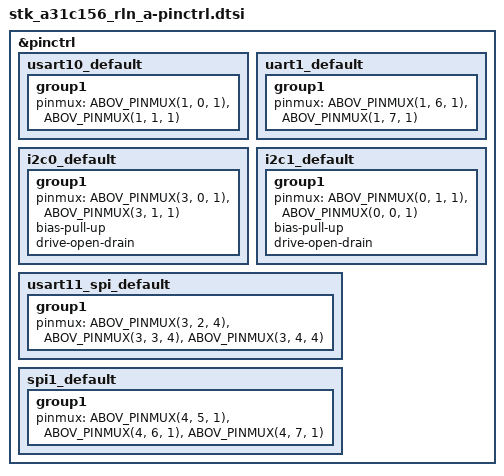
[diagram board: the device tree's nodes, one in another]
/*
 * Copyright (c) 2026 ABOV Semiconductor Co., Ltd.
 * SPDX-License-Identifier: BSD-3-Clause
 */

#include <zephyr/dt-bindings/pinctrl/abov-pinctrl.h>

&pinctrl {
	/*
	 * USART10 Pin Configuration (PB0: TX, PB1: RX, ALT1), per the default
	 * debug console pin mapping in debug_a31c15x.h (DEBUG_UART_ID=0,
	 * DEBUG_PORT_ID=1/PORT B, TX pin 0, RX pin 1, ALT 1).
	 */
	usart10_default: usart10_default {
		group1 {
			pinmux = <ABOV_PINMUX(1, 0, 1)>, /* PB0 - USART10_TX (ALT1) */
				 <ABOV_PINMUX(1, 1, 1)>; /* PB1 - USART10_RX (ALT1) */
		};
	};

	/*
	 * UART0's TX/RX pins (PF0/PF1, ALT4 -- see Board/stk_a31c156_rln_a.h)
	 * are shared with the on-board SWD debug port on this STK, so UART0
	 * is not usable here. UART1 Pin Configuration (PB6: TX, PB7: RX,
	 * ALT1) instead, per startup_a31c15x.h's P6/P7 mux comments
	 * ("0:PB6 1:TXD1" / "0:PB7 1:RXD1") and Board/bare.h's
	 * UART1_TX_PORT/UART1_RX_PORT (1/Port B, pins 6/7, mux 1).
	 */
	uart1_default: uart1_default {
		group1 {
			pinmux = <ABOV_PINMUX(1, 6, 1)>, /* PB6 - UART1_TX (ALT1) */
				 <ABOV_PINMUX(1, 7, 1)>; /* PB7 - UART1_RX (ALT1) */
		};
	};

	/* I2C0 Pin Configuration (PD0: SCL, PD1: SDA, ALT1) */
	i2c0_default: i2c0_default {
		group1 {
			pinmux = <ABOV_PINMUX(3, 0, 1)>, /* PD0 - I2C0_SCL (ALT1) */
				 <ABOV_PINMUX(3, 1, 1)>; /* PD1 - I2C0_SDA (ALT1) */
			bias-pull-up;
			drive-open-drain;
		};
	};

	/* I2C1 Pin Configuration (PA1: SCL1, PA0: SDA1, ALT1) */
	i2c1_default: i2c1_default {
		group1 {
			pinmux = <ABOV_PINMUX(0, 1, 1)>, /* PA1 - I2C1_SCL (ALT1) */
				 <ABOV_PINMUX(0, 0, 1)>; /* PA0 - I2C1_SDA (ALT1) */
			bias-pull-up;
			drive-open-drain;
		};
	};

	/*
	 * USART11-as-SPI Pin Configuration (PD2: MOSI11, PD3: MISO11,
	 * PD4: SCK11, ALT4), per startup_a31c15x.h's Port D mux comments
	 * ("4:MOSI11" / "4:MISO11" / "4:SCK11"). SS11 (PD5, ALT4) is
	 * deliberately not muxed here: the loopback sample uses no CS at all.
	 */
	usart11_spi_default: usart11_spi_default {
		group1 {
			pinmux = <ABOV_PINMUX(3, 2, 4)>, /* PD2 - MOSI11 (ALT4) */
				 <ABOV_PINMUX(3, 3, 4)>, /* PD3 - MISO11 (ALT4) */
				 <ABOV_PINMUX(3, 4, 4)>; /* PD4 - SCK11 (ALT4) */
		};
	};

	/*
	 * SPI1 Pin Configuration (PE5: SCK1, PE6: MISO1, PE7: MOSI1, ALT1),
	 * per the datasheet's Alternate Function table. SS1 (PE4, ALT1) is
	 * deliberately not muxed here: this sample (SPI1 master <-> USART11
	 * SPI slave) uses no CS at all.
	 */
	spi1_default: spi1_default {
		group1 {
			pinmux = <ABOV_PINMUX(4, 5, 1)>, /* PE5 - SPI1_SCK  (ALT1) */
				 <ABOV_PINMUX(4, 6, 1)>, /* PE6 - SPI1_MISO (ALT1) */
				 <ABOV_PINMUX(4, 7, 1)>; /* PE7 - SPI1_MOSI (ALT1) */
		};
	};
};
